VERSION "VCP virtual CAN interface"

NS_ :

BS_:

BU_: VCP

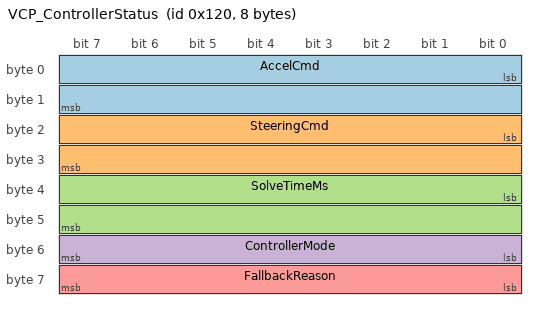
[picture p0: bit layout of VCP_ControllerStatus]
BO_ 288 VCP_ControllerStatus: 8 VCP
 SG_ AccelCmd : 0|16@1- (0.001,0) [-32.768|32.767] "m/s^2" VCP
 SG_ SteeringCmd : 16|16@1- (0.0001,0) [-3.2768|3.2767] "rad" VCP
 SG_ SolveTimeMs : 32|16@1+ (0.01,0) [0|655.35] "ms" VCP
 SG_ ControllerMode : 48|8@1+ (1,0) [0|255] "" VCP
 SG_ FallbackReason : 56|8@1+ (1,0) [0|255] "" VCP

CM_ BO_ 288 "Virtual CAN frame for controller command, timing, mode, and fallback status.";
CM_ SG_ 288 AccelCmd "Requested longitudinal acceleration.";
CM_ SG_ 288 SteeringCmd "Requested steering angle.";
CM_ SG_ 288 SolveTimeMs "Controller compute time.";
CM_ SG_ 288 ControllerMode "Controller/safety mode enum.";
CM_ SG_ 288 FallbackReason "Fallback reason enum.";

VAL_ 288 ControllerMode 0 "NORMAL" 1 "DEGRADED" 2 "FALLBACK_BRAKE" 3 "EMERGENCY_STOP" 4 "ESTIMATOR_FAULT" 5 "SOLVER_TIMEOUT" ;
VAL_ 288 FallbackReason 0 "no_fault" 1 "solver_infeasible" 2 "solver_timeout" 3 "estimator_residual" 4 "invalid_command" 5 "collision_risk" 6 "missing_sensor_message" 7 "communication_timeout" 8 "invalid_measurement" ;
